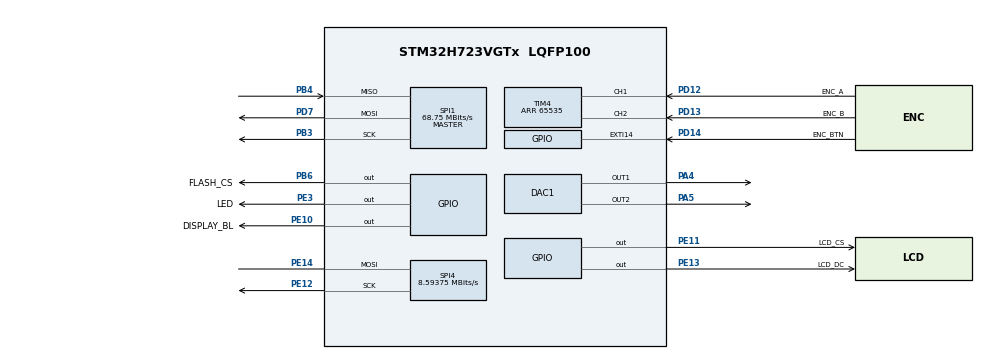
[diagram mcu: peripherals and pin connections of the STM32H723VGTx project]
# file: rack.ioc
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CORTEX_M7.default_mode_Activation=1
DAC1.DAC_Channel-DAC_OUT1=DAC_CHANNEL_1
DAC1.DAC_Channel-DAC_OUT2=DAC_CHANNEL_2
DAC1.DAC_Trigger-DAC_OUT1=DAC_TRIGGER_T6_TRGO
Dma.DAC1_CH1.0.Direction=DMA_MEMORY_TO_PERIPH
Dma.DAC1_CH1.0.EventEnable=DISABLE
Dma.DAC1_CH1.0.FIFOMode=DMA_FIFOMODE_DISABLE
Dma.DAC1_CH1.0.Instance=DMA1_Stream0
Dma.DAC1_CH1.0.MemDataAlignment=DMA_MDATAALIGN_HALFWORD
Dma.DAC1_CH1.0.MemInc=DMA_MINC_ENABLE
Dma.DAC1_CH1.0.Mode=DMA_CIRCULAR
Dma.DAC1_CH1.0.PeriphDataAlignment=DMA_PDATAALIGN_HALFWORD
Dma.DAC1_CH1.0.PeriphInc=DMA_PINC_DISABLE
Dma.DAC1_CH1.0.Polarity=HAL_DMAMUX_REQ_GEN_RISING
Dma.DAC1_CH1.0.Priority=DMA_PRIORITY_LOW
Dma.DAC1_CH1.0.RequestNumber=1
Dma.DAC1_CH1.0.SignalID=NONE
Dma.DAC1_CH1.0.SyncEnable=DISABLE
Dma.DAC1_CH1.0.SyncPolarity=HAL_DMAMUX_SYNC_NO_EVENT
Dma.DAC1_CH1.0.SyncRequestNumber=1
Dma.DAC1_CH1.0.SyncSignalID=NONE
Dma.Request0=DAC1_CH1
Mcu.Family=STM32H7
Mcu.Name=STM32H723VGTx
Mcu.Package=LQFP100
NVIC.DMA1_Stream0_IRQn=true\:0\:0\:false\:false\:true\:false\:true\:true
NVIC.EXTI15_10_IRQn=true\:5\:0\:true\:false\:true\:true\:true\:true
NVIC.PriorityGroup=NVIC_PRIORITYGROUP_4
NVIC.TIM7_IRQn=true\:5\:0\:true\:false\:true\:true\:true\:true
PA4.Signal=COMP_DAC11_group
PA5.Signal=COMP_DAC12_group
PA6.Signal=ADCx_INP3
PA7.Signal=ADCx_INN3
PB3(JTDO/TRACESWO).Mode=Full_Duplex_Master
PB3(JTDO/TRACESWO).Signal=SPI1_SCK
PB4(NJTRST).Mode=Full_Duplex_Master
PB4(NJTRST).Signal=SPI1_MISO
PB6.GPIO_Label=FLASH_CS
PB6.PinState=GPIO_PIN_SET
PB6.Signal=GPIO_Output
PD12.GPIO_Label=ENC_A
PD12.GPIO_PuPd=GPIO_PULLUP
PD12.Signal=S_TIM4_CH1
PD13.GPIO_Label=ENC_B
PD13.GPIO_PuPd=GPIO_PULLUP
PD13.Signal=S_TIM4_CH2
PD14.GPIO_Label=ENC_BTN
PD14.GPIO_ModeDefaultEXTI=GPIO_MODE_IT_FALLING
PD14.GPIO_PuPd=GPIO_PULLUP
PD14.Signal=GPXTI14
PD7.Mode=Full_Duplex_Master
PD7.Signal=SPI1_MOSI
PE10.GPIO_Label=DISPLAY_BL
PE10.PinState=GPIO_PIN_RESET
PE10.Signal=GPIO_Output
PE11.GPIO_Label=LCD_CS
PE11.GPIO_Speed=GPIO_SPEED_FREQ_VERY_HIGH
PE11.PinState=GPIO_PIN_SET
PE11.Signal=GPIO_Output
PE12.Mode=Simplex_Bidirectional_Master
PE12.Signal=SPI4_SCK
PE13.GPIO_Label=LCD_DC
PE13.GPIO_Speed=GPIO_SPEED_FREQ_VERY_HIGH
PE13.PinState=GPIO_PIN_SET
PE13.Signal=GPIO_Output
PE14.Mode=Simplex_Bidirectional_Master
PE14.Signal=SPI4_MOSI
PE3.GPIO_Label=LED
PE3.Signal=GPIO_Output
PH0-OSC_IN.Mode=HSE-External-Oscillator
PH0-OSC_IN.Signal=RCC_OSC_IN
PH1-OSC_OUT.Mode=HSE-External-Oscillator
PH1-OSC_OUT.Signal=RCC_OSC_OUT
ProjectManager.HeapSize=0x400
ProjectManager.StackSize=0x800
ProjectManager.TargetToolchain=Makefile
RCC.ADCFreq_Value=38400000
RCC.APB1Freq_Value=137500000
RCC.APB2Freq_Value=137500000
RCC.APB3Freq_Value=137500000
RCC.APB4Freq_Value=137500000
RCC.CortexFreq_Value=550000000
RCC.D1PPRE=RCC_APB3_DIV2
RCC.D2PPRE1=RCC_APB1_DIV2
RCC.D2PPRE2=RCC_APB2_DIV2
RCC.D3PPRE=RCC_APB4_DIV2
RCC.DIVM1=4
RCC.DIVM2=4
RCC.DIVN1=34
RCC.DIVN2=12
RCC.DIVP1=1
RCC.DIVP2=5
RCC.FLatency=FLASH_LATENCY_3
RCC.HCLKFreq_Value=275000000
RCC.HPRE=RCC_HCLK_DIV2
RCC.PLLFRACN=3072
RCC.PWR_Regulator_Voltage_Scale=PWR_REGULATOR_VOLTAGE_SCALE0
RCC.SYSCLKFreq_VALUE=550000000
RCC.SYSCLKSource=RCC_SYSCLKSOURCE_PLLCLK
RCC.USBFreq_Value=275000000
SH.ADCx_INN3.0=ADC2_INN3
SH.ADCx_INP3.0=ADC1_INP3
SH.COMP_DAC11_group.0=DAC1_OUT1,DAC_OUT1
SH.COMP_DAC12_group.0=DAC1_OUT2,DAC_OUT2
SH.S_TIM4_CH1.0=TIM4_CH1,Encoder_Interface
SH.S_TIM4_CH2.0=TIM4_CH2,Encoder_Interface
SPI1.BaudRatePrescaler=SPI_BAUDRATEPRESCALER_4
SPI1.CLKPhase=SPI_PHASE_1EDGE
SPI1.CLKPolarity=SPI_POLARITY_LOW
SPI1.CalculateBaudRate=68.75 MBits/s
SPI1.DataSize=SPI_DATASIZE_8BIT
SPI1.Direction=SPI_DIRECTION_2LINES
SPI1.Mode=SPI_MODE_MASTER
SPI1.VirtualType=VM_MASTER
SPI4.BaudRatePrescaler=SPI_BAUDRATEPRESCALER_16
SPI4.CLKPhase=SPI_PHASE_1EDGE
SPI4.CLKPolarity=SPI_POLARITY_LOW
SPI4.CalculateBaudRate=8.59375 MBits/s
SPI4.DataSize=SPI_DATASIZE_8BIT
SPI4.Direction=SPI_DIRECTION_1LINE
SPI4.Mode=SPI_MODE_MASTER
SPI4.VirtualType=VM_MASTER
TIM4.EncoderMode=TIM_ENCODERMODE_TI12
TIM4.IC1Filter=10
TIM4.IC2Filter=10
TIM4.Period=65535
TIM6.Period=6235
TIM6.Prescaler=0
TIM6.TIM_MasterOutputTrigger=TIM_TRGO_UPDATE
TIM7.Period=999
TIM7.Prescaler=6874
VP_MEMORYMAP_VS_MEMORYMAP.Mode=CurAppReg
VP_TIM6_VS_ClockSourceINT.Mode=Enable_Timer
VP_TIM7_VS_ClockSourceINT.Mode=Enable_Timer
board=custom

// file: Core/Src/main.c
/* USER CODE BEGIN Header */
/**
 ******************************************************************************
 * @file           : main.c
 * @brief          : Main program body
 ******************************************************************************
 * @attention
 *
 * Copyright (c) 2026 STMicroelectronics.
 * All rights reserved.
 *
 * This software is licensed under terms that can be found in the LICENSE file
 * in the root directory of this software component.
 * If no LICENSE file comes with this software, it is provided AS-IS.
 *
 ******************************************************************************
 */
/* USER CODE END Header */
#include "main.h"

/* USER CODE BEGIN Includes */
#include "CppWrapper.h"
/* USER CODE END Includes */

DAC_HandleTypeDef hdac1;
DMA_HandleTypeDef hdma_dac1_ch1;

SPI_HandleTypeDef hspi1;
SPI_HandleTypeDef hspi4;

TIM_HandleTypeDef htim4;
TIM_HandleTypeDef htim6;
TIM_HandleTypeDef htim7;

void SystemClock_Config(void);
static void MPU_Config(void);
static void MX_GPIO_Init(void);
static void MX_DMA_Init(void);
static void MX_DAC1_Init(void);
static void MX_TIM6_Init(void);
static void MX_SPI1_Init(void);
static void MX_SPI4_Init(void);
static void MX_TIM4_Init(void);
static void MX_TIM7_Init(void);

/* USER CODE BEGIN 0 */
extern void Encoder_ButtonCallback(uint16_t GPIO_Pin);
extern void Display_TimerCallback(void);
/* USER CODE END 0 */

int main(void)
{

  /* MPU Configuration--------------------------------------------------------*/
  MPU_Config();

  /* MCU Configuration--------------------------------------------------------*/

  /* Reset of all peripherals, Initializes the Flash interface and the Systick. */
  HAL_Init();

  /* Configure the system clock */
  SystemClock_Config();

  /* Initialize all configured peripherals */
  MX_GPIO_Init();
  MX_DMA_Init();
  MX_DAC1_Init();
  MX_TIM6_Init();
  MX_SPI1_Init();
  MX_SPI4_Init();
  MX_TIM4_Init();
  MX_TIM7_Init();
  /* USER CODE BEGIN 2 */
  Cpp_Init();
  /* USER CODE END 2 */

  /* Infinite loop */
  /* USER CODE BEGIN WHILE */
  while (1)
  {
    Cpp_Loop();
    // Cpp_TriggerKick();
    // HAL_Delay(500); // 120 BPM Kick
    /* USER CODE END WHILE */

  }
}

void SystemClock_Config(void)
{
  RCC_OscInitTypeDef RCC_OscInitStruct = {0};
  RCC_ClkInitTypeDef RCC_ClkInitStruct = {0};

  /** Supply configuration update enable
  */
  HAL_PWREx_ConfigSupply(PWR_LDO_SUPPLY);

  /** Configure the main internal regulator output voltage
  */
  __HAL_PWR_VOLTAGESCALING_CONFIG(PWR_REGULATOR_VOLTAGE_SCALE0);

  while(!__HAL_PWR_GET_FLAG(PWR_FLAG_VOSRDY)) {}

  /** Initializes the RCC Oscillators according to the specified parameters
  * in the RCC_OscInitTypeDef structure.
  */
  RCC_OscInitStruct.OscillatorType = RCC_OSCILLATORTYPE_HSI;
  RCC_OscInitStruct.HSIState = RCC_HSI_DIV1;
  RCC_OscInitStruct.HSICalibrationValue = 64;
  RCC_OscInitStruct.PLL.PLLState = RCC_PLL_ON;
  RCC_OscInitStruct.PLL.PLLSource = RCC_PLLSOURCE_HSI;
  RCC_OscInitStruct.PLL.PLLM = 4;
  RCC_OscInitStruct.PLL.PLLN = 34;
  RCC_OscInitStruct.PLL.PLLP = 1;
  RCC_OscInitStruct.PLL.PLLQ = 2;
  RCC_OscInitStruct.PLL.PLLR = 2;
  RCC_OscInitStruct.PLL.PLLRGE = RCC_PLL1VCIRANGE_3;
  RCC_OscInitStruct.PLL.PLLVCOSEL = RCC_PLL1VCOWIDE;
  RCC_OscInitStruct.PLL.PLLFRACN = 3072;
  if (HAL_RCC_OscConfig(&RCC_OscInitStruct) != HAL_OK)
  {
    Error_Handler();
  }

  /** Initializes the CPU, AHB and APB buses clocks
  */
  RCC_ClkInitStruct.ClockType = RCC_CLOCKTYPE_HCLK|RCC_CLOCKTYPE_SYSCLK
                              |RCC_CLOCKTYPE_PCLK1|RCC_CLOCKTYPE_PCLK2
                              |RCC_CLOCKTYPE_D3PCLK1|RCC_CLOCKTYPE_D1PCLK1;
  RCC_ClkInitStruct.SYSCLKSource = RCC_SYSCLKSOURCE_PLLCLK;
  RCC_ClkInitStruct.SYSCLKDivider = RCC_SYSCLK_DIV1;
  RCC_ClkInitStruct.AHBCLKDivider = RCC_HCLK_DIV2;
  RCC_ClkInitStruct.APB3CLKDivider = RCC_APB3_DIV2;
  RCC_ClkInitStruct.APB1CLKDivider = RCC_APB1_DIV2;
  RCC_ClkInitStruct.APB2CLKDivider = RCC_APB2_DIV2;
  RCC_ClkInitStruct.APB4CLKDivider = RCC_APB4_DIV2;

  if (HAL_RCC_ClockConfig(&RCC_ClkInitStruct, FLASH_LATENCY_3) != HAL_OK)
  {
    Error_Handler();
  }
}

static void MX_DAC1_Init(void)
{

  DAC_ChannelConfTypeDef sConfig = {0};

  /** DAC Initialization
  */
  hdac1.Instance = DAC1;
  if (HAL_DAC_Init(&hdac1) != HAL_OK)
  {
    Error_Handler();
  }

  /** DAC channel OUT1 config
  */
  sConfig.DAC_SampleAndHold = DAC_SAMPLEANDHOLD_DISABLE;
  sConfig.DAC_Trigger = DAC_TRIGGER_T6_TRGO;
  sConfig.DAC_OutputBuffer = DAC_OUTPUTBUFFER_ENABLE;
  sConfig.DAC_ConnectOnChipPeripheral = DAC_CHIPCONNECT_DISABLE;
  sConfig.DAC_UserTrimming = DAC_TRIMMING_FACTORY;
  if (HAL_DAC_ConfigChannel(&hdac1, &sConfig, DAC_CHANNEL_1) != HAL_OK)
  {
    Error_Handler();
  }

  /** DAC channel OUT2 config
  */
  sConfig.DAC_Trigger = DAC_TRIGGER_NONE;
  if (HAL_DAC_ConfigChannel(&hdac1, &sConfig, DAC_CHANNEL_2) != HAL_OK)
  {
    Error_Handler();
  }

}

static void MX_SPI1_Init(void)
{

  /* SPI1 parameter configuration*/
  hspi1.Instance = SPI1;
  hspi1.Init.Mode = SPI_MODE_MASTER;
  hspi1.Init.Direction = SPI_DIRECTION_2LINES;
  hspi1.Init.DataSize = SPI_DATASIZE_8BIT;
  hspi1.Init.CLKPolarity = SPI_POLARITY_LOW;
  hspi1.Init.CLKPhase = SPI_PHASE_1EDGE;
  hspi1.Init.NSS = SPI_NSS_SOFT;
  hspi1.Init.BaudRatePrescaler = SPI_BAUDRATEPRESCALER_4;
  hspi1.Init.FirstBit = SPI_FIRSTBIT_MSB;
  hspi1.Init.TIMode = SPI_TIMODE_DISABLE;
  hspi1.Init.CRCCalculation = SPI_CRCCALCULATION_DISABLE;
  hspi1.Init.CRCPolynomial = 0x0;
  hspi1.Init.NSSPMode = SPI_NSS_PULSE_ENABLE;
  hspi1.Init.NSSPolarity = SPI_NSS_POLARITY_LOW;
  hspi1.Init.FifoThreshold = SPI_FIFO_THRESHOLD_01DATA;
  hspi1.Init.TxCRCInitializationPattern = SPI_CRC_INITIALIZATION_ALL_ZERO_PATTERN;
  hspi1.Init.RxCRCInitializationPattern = SPI_CRC_INITIALIZATION_ALL_ZERO_PATTERN;
  hspi1.Init.MasterSSIdleness = SPI_MASTER_SS_IDLENESS_00CYCLE;
  hspi1.Init.MasterInterDataIdleness = SPI_MASTER_INTERDATA_IDLENESS_00CYCLE;
  hspi1.Init.MasterReceiverAutoSusp = SPI_MASTER_RX_AUTOSUSP_DISABLE;
  hspi1.Init.MasterKeepIOState = SPI_MASTER_KEEP_IO_STATE_DISABLE;
  hspi1.Init.IOSwap = SPI_IO_SWAP_DISABLE;
  if (HAL_SPI_Init(&hspi1) != HAL_OK)
  {
    Error_Handler();
  }

}

static void MX_SPI4_Init(void)
{

  /* SPI4 parameter configuration*/
  hspi4.Instance = SPI4;
  hspi4.Init.Mode = SPI_MODE_MASTER;
  hspi4.Init.Direction = SPI_DIRECTION_1LINE;
  hspi4.Init.DataSize = SPI_DATASIZE_8BIT;
  hspi4.Init.CLKPolarity = SPI_POLARITY_LOW;
  hspi4.Init.CLKPhase = SPI_PHASE_1EDGE;
  hspi4.Init.NSS = SPI_NSS_SOFT;
  hspi4.Init.BaudRatePrescaler = SPI_BAUDRATEPRESCALER_16;
  hspi4.Init.FirstBit = SPI_FIRSTBIT_MSB;
  hspi4.Init.TIMode = SPI_TIMODE_DISABLE;
  hspi4.Init.CRCCalculation = SPI_CRCCALCULATION_DISABLE;
  hspi4.Init.CRCPolynomial = 0x0;
  hspi4.Init.NSSPMode = SPI_NSS_PULSE_ENABLE;
  hspi4.Init.NSSPolarity = SPI_NSS_POLARITY_LOW;
  hspi4.Init.FifoThreshold = SPI_FIFO_THRESHOLD_01DATA;
  hspi4.Init.TxCRCInitializationPattern = SPI_CRC_INITIALIZATION_ALL_ZERO_PATTERN;
  hspi4.Init.RxCRCInitializationPattern = SPI_CRC_INITIALIZATION_ALL_ZERO_PATTERN;
  hspi4.Init.MasterSSIdleness = SPI_MASTER_SS_IDLENESS_00CYCLE;
  hspi4.Init.MasterInterDataIdleness = SPI_MASTER_INTERDATA_IDLENESS_00CYCLE;
  hspi4.Init.MasterReceiverAutoSusp = SPI_MASTER_RX_AUTOSUSP_DISABLE;
  hspi4.Init.MasterKeepIOState = SPI_MASTER_KEEP_IO_STATE_DISABLE;
  hspi4.Init.IOSwap = SPI_IO_SWAP_DISABLE;
  if (HAL_SPI_Init(&hspi4) != HAL_OK)
  {
    Error_Handler();
  }

}

static void MX_TIM4_Init(void)
{

  TIM_Encoder_InitTypeDef sConfig = {0};
  TIM_MasterConfigTypeDef sMasterConfig = {0};

  htim4.Instance = TIM4;
  htim4.Init.Prescaler = 0;
  htim4.Init.CounterMode = TIM_COUNTERMODE_UP;
  htim4.Init.Period = 65535;
  htim4.Init.ClockDivision = TIM_CLOCKDIVISION_DIV1;
  htim4.Init.AutoReloadPreload = TIM_AUTORELOAD_PRELOAD_DISABLE;
  sConfig.EncoderMode = TIM_ENCODERMODE_TI12;
  sConfig.IC1Polarity = TIM_ICPOLARITY_RISING;
  sConfig.IC1Selection = TIM_ICSELECTION_DIRECTTI;
  sConfig.IC1Prescaler = TIM_ICPSC_DIV1;
  sConfig.IC1Filter = 10;
  sConfig.IC2Polarity = TIM_ICPOLARITY_RISING;
  sConfig.IC2Selection = TIM_ICSELECTION_DIRECTTI;
  sConfig.IC2Prescaler = TIM_ICPSC_DIV1;
  sConfig.IC2Filter = 10;
  if (HAL_TIM_Encoder_Init(&htim4, &sConfig) != HAL_OK)
  {
    Error_Handler();
  }
  sMasterConfig.MasterOutputTrigger = TIM_TRGO_RESET;
  sMasterConfig.MasterSlaveMode = TIM_MASTERSLAVEMODE_DISABLE;
  if (HAL_TIMEx_MasterConfigSynchronization(&htim4, &sMasterConfig) != HAL_OK)
  {
    Error_Handler();
  }

}

static void MX_TIM6_Init(void)
{

  TIM_MasterConfigTypeDef sMasterConfig = {0};

  htim6.Instance = TIM6;
  htim6.Init.Prescaler = 0;
  htim6.Init.CounterMode = TIM_COUNTERMODE_UP;
  htim6.Init.Period = 6235;
  htim6.Init.AutoReloadPreload = TIM_AUTORELOAD_PRELOAD_DISABLE;
  if (HAL_TIM_Base_Init(&htim6) != HAL_OK)
  {
    Error_Handler();
  }
  sMasterConfig.MasterOutputTrigger = TIM_TRGO_UPDATE;
  sMasterConfig.MasterSlaveMode = TIM_MASTERSLAVEMODE_DISABLE;
  if (HAL_TIMEx_MasterConfigSynchronization(&htim6, &sMasterConfig) != HAL_OK)
  {
    Error_Handler();
  }

}

static void MX_TIM7_Init(void)
{

  TIM_MasterConfigTypeDef sMasterConfig = {0};

  htim7.Instance = TIM7;
  htim7.Init.Prescaler = 6874;
  htim7.Init.CounterMode = TIM_COUNTERMODE_UP;
  htim7.Init.Period = 999;
  htim7.Init.AutoReloadPreload = TIM_AUTORELOAD_PRELOAD_DISABLE;
  if (HAL_TIM_Base_Init(&htim7) != HAL_OK)
  {
    Error_Handler();
  }
  sMasterConfig.MasterOutputTrigger = TIM_TRGO_RESET;
  sMasterConfig.MasterSlaveMode = TIM_MASTERSLAVEMODE_DISABLE;
  if (HAL_TIMEx_MasterConfigSynchronization(&htim7, &sMasterConfig) != HAL_OK)
  {
    Error_Handler();
  }

}

static void MX_DMA_Init(void)
{

  /* DMA controller clock enable */
  __HAL_RCC_DMA1_CLK_ENABLE();

  /* DMA interrupt init */
  /* DMA1_Stream0_IRQn interrupt configuration */
  HAL_NVIC_SetPriority(DMA1_Stream0_IRQn, 0, 0);
  HAL_NVIC_EnableIRQ(DMA1_Stream0_IRQn);

}

static void MX_GPIO_Init(void)
{
  GPIO_InitTypeDef GPIO_InitStruct = {0};

  /* GPIO Ports Clock Enable */
  __HAL_RCC_GPIOE_CLK_ENABLE();
  __HAL_RCC_GPIOH_CLK_ENABLE();
  __HAL_RCC_GPIOA_CLK_ENABLE();
  __HAL_RCC_GPIOD_CLK_ENABLE();
  __HAL_RCC_GPIOB_CLK_ENABLE();

  /*Configure GPIO pin Output Level */
  HAL_GPIO_WritePin(GPIOE, LED_Pin|DISPLAY_BL_Pin, GPIO_PIN_RESET);

  /*Configure GPIO pin Output Level */
  HAL_GPIO_WritePin(GPIOE, LCD_CS_Pin|LCD_DC_Pin, GPIO_PIN_SET);

  /*Configure GPIO pin Output Level */
  HAL_GPIO_WritePin(FLASH_CS_GPIO_Port, FLASH_CS_Pin, GPIO_PIN_SET);

  /*Configure GPIO pins : LED_Pin DISPLAY_BL_Pin */
  GPIO_InitStruct.Pin = LED_Pin|DISPLAY_BL_Pin;
  GPIO_InitStruct.Mode = GPIO_MODE_OUTPUT_PP;
  GPIO_InitStruct.Pull = GPIO_NOPULL;
  GPIO_InitStruct.Speed = GPIO_SPEED_FREQ_LOW;
  HAL_GPIO_Init(GPIOE, &GPIO_InitStruct);

  /*Configure GPIO pins : PA6 PA7 */
  GPIO_InitStruct.Pin = GPIO_PIN_6|GPIO_PIN_7;
  GPIO_InitStruct.Mode = GPIO_MODE_ANALOG;
  GPIO_InitStruct.Pull = GPIO_NOPULL;
  HAL_GPIO_Init(GPIOA, &GPIO_InitStruct);

  /*Configure GPIO pins : LCD_CS_Pin LCD_DC_Pin */
  GPIO_InitStruct.Pin = LCD_CS_Pin|LCD_DC_Pin;
  GPIO_InitStruct.Mode = GPIO_MODE_OUTPUT_PP;
  GPIO_InitStruct.Pull = GPIO_NOPULL;
  GPIO_InitStruct.Speed = GPIO_SPEED_FREQ_VERY_HIGH;
  HAL_GPIO_Init(GPIOE, &GPIO_InitStruct);

  /*Configure GPIO pin : ENC_BTN_Pin */
  GPIO_InitStruct.Pin = ENC_BTN_Pin;
  GPIO_InitStruct.Mode = GPIO_MODE_IT_FALLING;
  GPIO_InitStruct.Pull = GPIO_PULLUP;
  HAL_GPIO_Init(ENC_BTN_GPIO_Port, &GPIO_InitStruct);

  /*Configure GPIO pin : FLASH_CS_Pin */
  GPIO_InitStruct.Pin = FLASH_CS_Pin;
  GPIO_InitStruct.Mode = GPIO_MODE_OUTPUT_PP;
  GPIO_InitStruct.Pull = GPIO_NOPULL;
  GPIO_InitStruct.Speed = GPIO_SPEED_FREQ_LOW;
  HAL_GPIO_Init(FLASH_CS_GPIO_Port, &GPIO_InitStruct);

  /* EXTI interrupt init*/
  HAL_NVIC_SetPriority(ENC_BTN_EXTI_IRQn, 5, 0);
  HAL_NVIC_EnableIRQ(ENC_BTN_EXTI_IRQn);

}

/* USER CODE BEGIN 4 */
// GPIO External Interrupt Callback
void HAL_GPIO_EXTI_Callback(uint16_t GPIO_Pin)
{
    if (GPIO_Pin == GPIO_PIN_14) {
        Encoder_ButtonCallback(GPIO_Pin);
    }
}
/**
 * @brief Timer interrupt callback
 * Called automatically when any timer overflow occurs
 */
void HAL_TIM_PeriodElapsedCallback(TIM_HandleTypeDef *htim)
{
    if (htim->Instance == TIM7) {
        // Display update timer (20 Hz)
        Display_TimerCallback();
    }
    // Add other timers here if needed
}
/* USER CODE END 4 */

 /* MPU Configuration */

void MPU_Config(void)
{
  MPU_Region_InitTypeDef MPU_InitStruct = {0};

  /* Disables the MPU */
  HAL_MPU_Disable();

  /** Initializes and configures the Region and the memory to be protected
  */
  MPU_InitStruct.Enable = MPU_REGION_ENABLE;
  MPU_InitStruct.Number = MPU_REGION_NUMBER0;
  MPU_InitStruct.BaseAddress = 0x0;
  MPU_InitStruct.Size = MPU_REGION_SIZE_4GB;
  MPU_InitStruct.SubRegionDisable = 0x87;
  MPU_InitStruct.TypeExtField = MPU_TEX_LEVEL0;
  MPU_InitStruct.AccessPermission = MPU_REGION_NO_ACCESS;
  MPU_InitStruct.DisableExec = MPU_INSTRUCTION_ACCESS_DISABLE;
  MPU_InitStruct.IsShareable = MPU_ACCESS_SHAREABLE;
  MPU_InitStruct.IsCacheable = MPU_ACCESS_NOT_CACHEABLE;
  MPU_InitStruct.IsBufferable = MPU_ACCESS_NOT_BUFFERABLE;

  HAL_MPU_ConfigRegion(&MPU_InitStruct);
  /* Enables the MPU */
  HAL_MPU_Enable(MPU_PRIVILEGED_DEFAULT);

}

void Error_Handler(void)
{
  __disable_irq();
  while (1)
  {
  }
}
